# GD32H71x_72x register map
File version: 1.0
CPU: CM7 r1p2, little endian, MPU, FPU, 4 interrupt priority bits
Registers are 32-bit, read-write, reset 0x0 unless marked. A register's access mark holds for its fields unless they carry their own. Offsets are from the block's base; [hi:lo] are bit positions.

## ESC_CORE — EtherCAT core
Base 0x5F00D300
0x00 CCTL_DATA — ESC CCTL data register
  [31:0] CCTL_DATA — ESC CCTL data
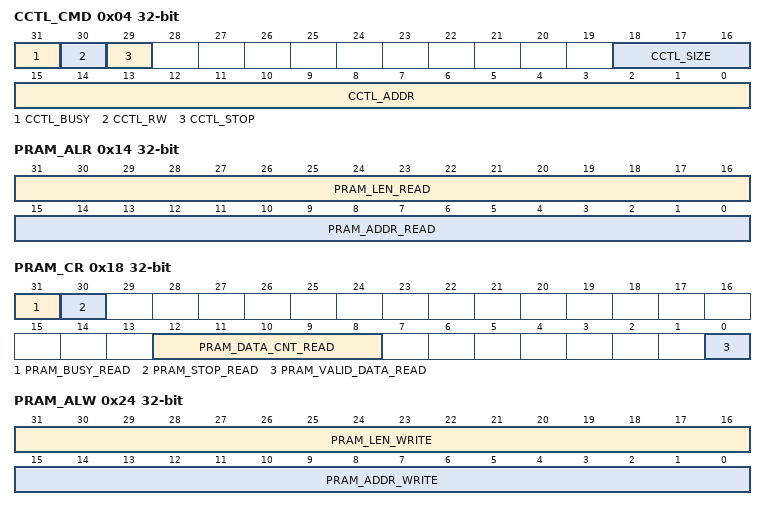
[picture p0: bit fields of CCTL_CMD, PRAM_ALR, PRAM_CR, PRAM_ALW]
0x04 CCTL_CMD — ESC CCTL command register
  [31] CCTL_BUSY — CCTL Busy. There is no effect if the bit is written to 0
  [30] CCTL_RW — Read or write selection
  [29] CCTL_STOP — Stop read or write operation. There is no effect if the bit is written to 0.
  [18:16] CCTL_SIZE — This field specifies the size of the register that is about to be read or write. (in byte). Only 1, 2 and 4 are valid, other values are invalid.
  [15:0] CCTL_ADDR — This field specifies the address of ESC registers that will be accessed.
0x10 PRAM_FIFO_DR ro — ESC PRAM FIFO data read register
  [31:0] PRAM_FIFO_DATA_READ — Data read from ESC PRAM.
0x14 PRAM_ALR — ESC PRAM address and length read register
  [31:16] PRAM_LEN_READ — Data length read from ESC PRAM in bytes. This field is decremented as data is read into the FIFO.
  [15:0] PRAM_ADDR_READ — ESC PRAM data read address. This field is incremented as data is read into the FIFO.
0x18 PRAM_CR access per field — ESC PRAM command read register
  [31] PRAM_BUSY_READ rw — Whether the PRAM is being read. There is no effect if the bit is written to 0
  [30] PRAM_STOP_READ rw — Stop PRAM read operation. There is no effect if the bit is written to zero
  [12:8] PRAM_DATA_CNT_READ ro — PRAM data read valid count
  [0] PRAM_VALID_DATA_READ ro
0x20 PRAM_FIFO_DW wo — ESC PRAM FIFO data write register
  [31:0] PRAM_FIFO_DATA_WRITE — Data write to ESC PRAM.
0x24 PRAM_ALW — ESC PRAM address and length write register
  [31:16] PRAM_LEN_WRITE — Data length written to ESC PRAM in bytes. This field is decremented as data is written into the FIFO.
  [15:0] PRAM_ADDR_WRITE — ESC PRAM data write address. This field is incremented as data is read from the FIFO.
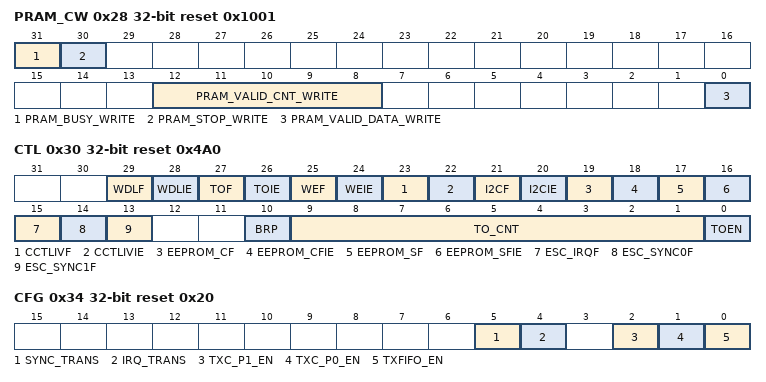
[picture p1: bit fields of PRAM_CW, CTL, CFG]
0x28 PRAM_CW access per field reset 0x1001 — ESC PRAM command write register
  [31] PRAM_BUSY_WRITE rw — Whether the PRAM is being written. There is no effect if the bit is written to zero
  [30] PRAM_STOP_WRITE rw — Stop PRAM write operation. There is no effect if the bit is written to zero
  [12:8] PRAM_VALID_CNT_WRITE ro — PRAM data write valid count
  [0] PRAM_VALID_DATA_WRITE ro
0x30 CTL reset 0x4A0 — ESC Control register
  [29] WDLF — Write data lost flag
  [28] WDLIE — Write data lost interrupt enable
  [27] TOF — Time out flag, when single transmission time exceeds the programmed value, this flag will be triggered. This flag can be cleared by writing 1.
  [26] TOIE — Timer out interrupt enable
  [25] WEF — write error flag. when BRP disable, AHB write operation will cause current OPB transmission error when the busy bit is high, this flag will be triggered. This flag can be cleared by writing 1.
  [24] WEIE — Write error interrupt enable.
  [23] CCTLIVF — CCTL_SIZE and CCTL_ADDR illegal value flag
  [22] CCTLIVIE — CCTL_SIZE and CCTL_ADDR Illegal value interrupt enable.
  [21] I2CF — Internal I2C communication error flag.
  [20] I2CIE — Internal I2C overrun interrupt enable.
  [19] EEPROM_CF — The flag signal indicating the completion of EEPROM reloading by ESC
  [18] EEPROM_CFIE — EEPROM_CF interrupt flag enable
  [17] EEPROM_SF — The flag indicating the start of EEPROM reloading by ESC
  [16] EEPROM_SFIE — EEPROM_SF interrupt flag enable
  [15] ESC_IRQF — The flag IRQ signal generated by ESC is used to trigger a MCU interrupt
  [14] ESC_SYNC0F — The flag SYNC0 signal generated by ESC is used to trigger a MCU interrupt
  [13] ESC_SYNC1F — The flag SYNC1 signal generated by ESC is used to trigger a MCU interrupt SYNC1 event
  [10] BRP — When busy bit is high, prevent register change
  [9:1] TO_CNT — Time Out counter
  [0] TOEN — Time Out enable
0x34 CFG reset 0x20 — ESC Config register
  [5] SYNC_TRANS — ESC sync transfer bit
  [4] IRQ_TRANS — ESC irq transfer bit
  [2] TXC_P1_EN — TX_CLK port 1 enable bit
  [1] TXC_P0_EN — TX_CLK port 0 enable bit
  [0] TXFIFO_EN — TX FIFO enable bit
